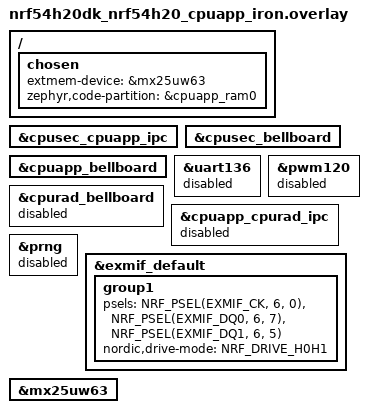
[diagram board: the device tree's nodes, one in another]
/*
 * Copyright (c) 2024 Nordic Semiconductor ASA
 *
 * SPDX-License-Identifier: LicenseRef-Nordic-5-Clause
 */

/ {
	chosen {
		extmem-device = &mx25uw63;
		zephyr,code-partition = &cpuapp_ram0;
	};
};

&cpusec_cpuapp_ipc {
	status = "okay";
};

&cpusec_bellboard {
	status = "okay";
};

&cpuapp_bellboard {
	status = "okay";
};

&uart136 {
	status = "disabled";
};

&cpurad_bellboard {
	status = "disabled";
};

&pwm120 {
	status = "disabled";
};

&cpuapp_cpurad_ipc {
	status = "disabled";
};

&prng {
	status = "disabled";
};


&exmif_default {
	group1 {
		psels = <NRF_PSEL(EXMIF_CK, 6, 0)>,
			<NRF_PSEL(EXMIF_DQ0, 6, 7)>,
			<NRF_PSEL(EXMIF_DQ1, 6, 5)>;
		nordic,drive-mode = <NRF_DRIVE_H0H1>;
	};
};

&mx25uw63 {
	status = "okay";
};
